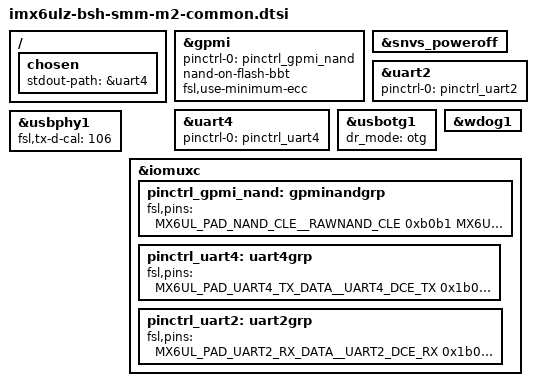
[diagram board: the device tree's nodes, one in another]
// SPDX-License-Identifier: (GPL-2.0 OR MIT)
/*
 * Copyright (C) 2021 BSH Hausgeraete GmbH
 */

#include <dt-bindings/input/input.h>
#include "imx6ulz.dtsi"

/ {
	chosen {
		stdout-path = &uart4;
	};
};

&gpmi {
	pinctrl-names = "default";
	pinctrl-0 = <&pinctrl_gpmi_nand>;
	nand-on-flash-bbt;
	fsl,use-minimum-ecc;
	status = "okay";
};

&snvs_poweroff {
	status = "okay";
};

&uart2 {
	pinctrl-names = "default";
	pinctrl-0 = <&pinctrl_uart2>;
	status = "okay";
};

&uart4 {
	pinctrl-names = "default";
	pinctrl-0 = <&pinctrl_uart4>;
	status = "okay";
};

&usbotg1 {
	dr_mode = "otg";
	status = "okay";
};

&usbphy1 {
	fsl,tx-d-cal = <106>;
};

&wdog1 {
	status = "okay";
};

&iomuxc {
	pinctrl_gpmi_nand: gpminandgrp {
		fsl,pins = <
			MX6UL_PAD_NAND_CLE__RAWNAND_CLE		0xb0b1
			MX6UL_PAD_NAND_ALE__RAWNAND_ALE		0xb0b1
			MX6UL_PAD_NAND_WP_B__RAWNAND_WP_B	0xb0b1
			MX6UL_PAD_NAND_READY_B__RAWNAND_READY_B	0xb000
			MX6UL_PAD_NAND_CE0_B__RAWNAND_CE0_B	0xb0b1
			MX6UL_PAD_NAND_RE_B__RAWNAND_RE_B	0xb0b1
			MX6UL_PAD_NAND_WE_B__RAWNAND_WE_B	0xb0b1
			MX6UL_PAD_NAND_DATA00__RAWNAND_DATA00	0xb0b1
			MX6UL_PAD_NAND_DATA01__RAWNAND_DATA01	0xb0b1
			MX6UL_PAD_NAND_DATA02__RAWNAND_DATA02	0xb0b1
			MX6UL_PAD_NAND_DATA03__RAWNAND_DATA03	0xb0b1
			MX6UL_PAD_NAND_DATA04__RAWNAND_DATA04	0xb0b1
			MX6UL_PAD_NAND_DATA05__RAWNAND_DATA05	0xb0b1
			MX6UL_PAD_NAND_DATA06__RAWNAND_DATA06	0xb0b1
			MX6UL_PAD_NAND_DATA07__RAWNAND_DATA07	0xb0b1
		>;
	};

	pinctrl_uart4: uart4grp {
		fsl,pins = <
			MX6UL_PAD_UART4_TX_DATA__UART4_DCE_TX	0x1b0b1
			MX6UL_PAD_UART4_RX_DATA__UART4_DCE_RX	0x1b0b1
		>;
	};

	pinctrl_uart2: uart2grp {
		fsl,pins = <
			MX6UL_PAD_UART2_RX_DATA__UART2_DCE_RX	0x1b0b1
			MX6UL_PAD_UART2_TX_DATA__UART2_DCE_TX	0x1b0b1
		>;
	};
};
